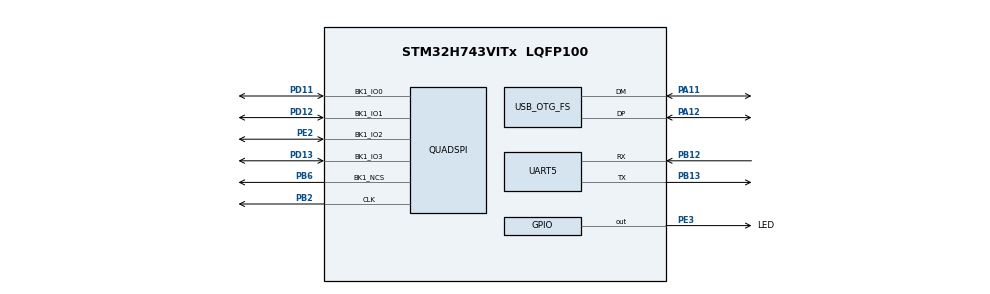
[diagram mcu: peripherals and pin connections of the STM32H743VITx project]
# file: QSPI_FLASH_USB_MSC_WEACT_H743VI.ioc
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CORTEX_M7.AccessPermission_S-Cortex_Memory_Protection_Unit_Region1_Settings_S=MPU_REGION_FULL_ACCESS
CORTEX_M7.BaseAddress_S-Cortex_Memory_Protection_Unit_Region1_Settings_S=0x90000000
CORTEX_M7.Enable_S-Cortex_Memory_Protection_Unit_Region1_Settings_S=MPU_REGION_ENABLE
CORTEX_M7.Size_S-Cortex_Memory_Protection_Unit_Region1_Settings_S=MPU_REGION_SIZE_8MB
CORTEX_M7.default_mode_Activation=1
Mcu.Family=STM32H7
Mcu.Name=STM32H743VITx
Mcu.Package=LQFP100
NVIC.OTG_FS_IRQn=true\:0\:0\:false\:false\:true\:false\:true\:true
NVIC.PriorityGroup=NVIC_PRIORITYGROUP_4
PA11.Mode=Device_Only
PA11.Signal=USB_OTG_FS_DM
PA12.Mode=Device_Only
PA12.Signal=USB_OTG_FS_DP
PB12.Mode=Asynchronous
PB12.Signal=UART5_RX
PB13.Mode=Asynchronous
PB13.Signal=UART5_TX
PB2.GPIO_Speed=GPIO_SPEED_FREQ_VERY_HIGH
PB2.Mode=Single Bank 1
PB2.Signal=QUADSPI_CLK
PB6.GPIO_FM6=SYSCFG_PMCR_I2C_PB6_FMP
PB6.GPIO_Speed=GPIO_SPEED_FREQ_VERY_HIGH
PB6.Mode=Single Bank 1
PB6.Signal=QUADSPI_BK1_NCS
PC14-OSC32_IN\ (OSC32_IN).Mode=LSE-External-Oscillator
PC14-OSC32_IN\ (OSC32_IN).Signal=RCC_OSC32_IN
PC15-OSC32_OUT\ (OSC32_OUT).Mode=LSE-External-Oscillator
PC15-OSC32_OUT\ (OSC32_OUT).Signal=RCC_OSC32_OUT
PD11.GPIO_Speed=GPIO_SPEED_FREQ_VERY_HIGH
PD11.Mode=Single Bank 1
PD11.Signal=QUADSPI_BK1_IO0
PD12.GPIO_Speed=GPIO_SPEED_FREQ_VERY_HIGH
PD12.Mode=Single Bank 1
PD12.Signal=QUADSPI_BK1_IO1
PD13.GPIO_Speed=GPIO_SPEED_FREQ_VERY_HIGH
PD13.Mode=Single Bank 1
PD13.Signal=QUADSPI_BK1_IO3
PE2.GPIO_Speed=GPIO_SPEED_FREQ_VERY_HIGH
PE2.Mode=Single Bank 1
PE2.Signal=QUADSPI_BK1_IO2
PE3.GPIO_Label=LED
PE3.Signal=GPIO_Output
PH0-OSC_IN\ (PH0).Mode=HSE-External-Oscillator
PH0-OSC_IN\ (PH0).Signal=RCC_OSC_IN
PH1-OSC_OUT\ (PH1).Mode=HSE-External-Oscillator
PH1-OSC_OUT\ (PH1).Signal=RCC_OSC_OUT
ProjectManager.HeapSize=0x200
ProjectManager.StackSize=0x2000
ProjectManager.TargetToolchain=STM32CubeIDE
QUADSPI.ClockPrescaler=2-1
QUADSPI.FlashSize=23-1
QUADSPI.SampleShifting=QSPI_SAMPLE_SHIFTING_HALFCYCLE
RCC.ADCFreq_Value=480000000
RCC.APB1Freq_Value=120000000
RCC.APB2Freq_Value=120000000
RCC.APB3Freq_Value=120000000
RCC.APB4Freq_Value=120000000
RCC.CortexFreq_Value=480000000
RCC.D1PPRE=RCC_APB3_DIV2
RCC.D2PPRE1=RCC_APB1_DIV2
RCC.D2PPRE2=RCC_APB2_DIV2
RCC.D3PPRE=RCC_APB4_DIV2
RCC.DIVM1=5
RCC.DIVM2=5
RCC.DIVM3=5
RCC.DIVN1=192
RCC.DIVN2=192
RCC.DIVN3=192
RCC.DIVQ1=20
RCC.DIVQ2=8
RCC.DIVQ3=8
RCC.DIVR2=8
RCC.HCLKFreq_Value=240000000
RCC.HPRE=RCC_HCLK_DIV2
RCC.PLLFRACN=0
RCC.PLLSourceVirtual=RCC_PLLSOURCE_HSE
RCC.QSPICLockSelection=RCC_QSPICLKSOURCE_PLL2
RCC.SYSCLKFreq_VALUE=480000000
RCC.SYSCLKSource=RCC_SYSCLKSOURCE_PLLCLK
RCC.USBFreq_Value=48000000
USB_DEVICE.CLASS_NAME_FS=MSC
USB_DEVICE.MSC_MEDIA_PACKET-MSC_FS=512
USB_DEVICE.VirtualMode-MSC_FS=Msc
USB_DEVICE.VirtualModeFS=Msc_FS
USB_OTG_FS.VirtualMode=Device_Only
USB_OTG_FS.dma_enable=ENABLE
VP_MEMORYMAP_VS_MEMORYMAP.Mode=CurAppReg
VP_USB_DEVICE_VS_USB_DEVICE_MSC_FS.Mode=MSC_FS
board=custom

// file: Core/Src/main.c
/* USER CODE BEGIN Header */
/**
  ******************************************************************************
  * @file           : main.c
  * @brief          : Main program body
  ******************************************************************************
  * @attention
  *
  * Copyright (c) 2026 STMicroelectronics.
  * All rights reserved.
  *
  * This software is licensed under terms that can be found in the LICENSE file
  * in the root directory of this software component.
  * If no LICENSE file comes with this software, it is provided AS-IS.
  *
  ******************************************************************************
  */
/* USER CODE END Header */
#include "main.h"
#include "usb_device.h"

/* USER CODE BEGIN Includes */
#include <stdio.h>
#include "w25qxx_qspi.h"
/* USER CODE END Includes */

QSPI_HandleTypeDef hqspi;

UART_HandleTypeDef huart5;

void SystemClock_Config(void);
static void MPU_Config(void);
static void MX_GPIO_Init(void);
static void MX_QUADSPI_Init(void);
static void MX_UART5_Init(void);
/* USER CODE BEGIN PFP */
void W25QXX_Demo(void);
/* USER CODE END PFP */

/* USER CODE BEGIN 0 */
void LED_Blink(uint32_t delay)
{
	HAL_GPIO_WritePin(LED_GPIO_Port,LED_Pin,GPIO_PIN_SET);
	HAL_Delay(delay - 1);
	HAL_GPIO_WritePin(LED_GPIO_Port,LED_Pin,GPIO_PIN_RESET);
	HAL_Delay(500-1);
}
/* USER CODE END 0 */

int main(void)
{

  /* MPU Configuration--------------------------------------------------------*/
  MPU_Config();

  /* MCU Configuration--------------------------------------------------------*/

  /* Reset of all peripherals, Initializes the Flash interface and the Systick. */
  HAL_Init();

  /* Configure the system clock */
  SystemClock_Config();

  /* Initialize all configured peripherals */
  MX_GPIO_Init();
  MX_QUADSPI_Init();
  MX_UART5_Init();
  MX_USB_DEVICE_Init();
  /* USER CODE BEGIN 2 */

  //W25QXX_Demo();

  /* USER CODE END 2 */

  /* Infinite loop */
  while (1)
  {

    /* USER CODE BEGIN 3 */
	LED_Blink(5);
  }
  /* USER CODE END 3 */
}

void SystemClock_Config(void)
{
  RCC_OscInitTypeDef RCC_OscInitStruct = {0};
  RCC_ClkInitTypeDef RCC_ClkInitStruct = {0};

  /** Supply configuration update enable
  */
  HAL_PWREx_ConfigSupply(PWR_LDO_SUPPLY);

  /** Configure the main internal regulator output voltage
  */
  __HAL_PWR_VOLTAGESCALING_CONFIG(PWR_REGULATOR_VOLTAGE_SCALE0);

  while(!__HAL_PWR_GET_FLAG(PWR_FLAG_VOSRDY)) {}

  /** Initializes the RCC Oscillators according to the specified parameters
  * in the RCC_OscInitTypeDef structure.
  */
  RCC_OscInitStruct.OscillatorType = RCC_OSCILLATORTYPE_HSE;
  RCC_OscInitStruct.HSEState = RCC_HSE_ON;
  RCC_OscInitStruct.PLL.PLLState = RCC_PLL_ON;
  RCC_OscInitStruct.PLL.PLLSource = RCC_PLLSOURCE_HSE;
  RCC_OscInitStruct.PLL.PLLM = 5;
  RCC_OscInitStruct.PLL.PLLN = 192;
  RCC_OscInitStruct.PLL.PLLP = 2;
  RCC_OscInitStruct.PLL.PLLQ = 20;
  RCC_OscInitStruct.PLL.PLLR = 2;
  RCC_OscInitStruct.PLL.PLLRGE = RCC_PLL1VCIRANGE_2;
  RCC_OscInitStruct.PLL.PLLVCOSEL = RCC_PLL1VCOWIDE;
  RCC_OscInitStruct.PLL.PLLFRACN = 0;
  if (HAL_RCC_OscConfig(&RCC_OscInitStruct) != HAL_OK)
  {
    Error_Handler();
  }

  /** Initializes the CPU, AHB and APB buses clocks
  */
  RCC_ClkInitStruct.ClockType = RCC_CLOCKTYPE_HCLK|RCC_CLOCKTYPE_SYSCLK
                              |RCC_CLOCKTYPE_PCLK1|RCC_CLOCKTYPE_PCLK2
                              |RCC_CLOCKTYPE_D3PCLK1|RCC_CLOCKTYPE_D1PCLK1;
  RCC_ClkInitStruct.SYSCLKSource = RCC_SYSCLKSOURCE_PLLCLK;
  RCC_ClkInitStruct.SYSCLKDivider = RCC_SYSCLK_DIV1;
  RCC_ClkInitStruct.AHBCLKDivider = RCC_HCLK_DIV2;
  RCC_ClkInitStruct.APB3CLKDivider = RCC_APB3_DIV2;
  RCC_ClkInitStruct.APB1CLKDivider = RCC_APB1_DIV2;
  RCC_ClkInitStruct.APB2CLKDivider = RCC_APB2_DIV2;
  RCC_ClkInitStruct.APB4CLKDivider = RCC_APB4_DIV2;

  if (HAL_RCC_ClockConfig(&RCC_ClkInitStruct, FLASH_LATENCY_4) != HAL_OK)
  {
    Error_Handler();
  }
}

static void MX_QUADSPI_Init(void)
{

  /* QUADSPI parameter configuration*/
  hqspi.Instance = QUADSPI;
  hqspi.Init.ClockPrescaler = 2-1;
  hqspi.Init.FifoThreshold = 1;
  hqspi.Init.SampleShifting = QSPI_SAMPLE_SHIFTING_HALFCYCLE;
  hqspi.Init.FlashSize = 23-1;
  hqspi.Init.ChipSelectHighTime = QSPI_CS_HIGH_TIME_1_CYCLE;
  hqspi.Init.ClockMode = QSPI_CLOCK_MODE_0;
  hqspi.Init.FlashID = QSPI_FLASH_ID_1;
  hqspi.Init.DualFlash = QSPI_DUALFLASH_DISABLE;
  if (HAL_QSPI_Init(&hqspi) != HAL_OK)
  {
    Error_Handler();
  }

}

static void MX_UART5_Init(void)
{

  huart5.Instance = UART5;
  huart5.Init.BaudRate = 115200;
  huart5.Init.WordLength = UART_WORDLENGTH_8B;
  huart5.Init.StopBits = UART_STOPBITS_1;
  huart5.Init.Parity = UART_PARITY_NONE;
  huart5.Init.Mode = UART_MODE_TX_RX;
  huart5.Init.HwFlowCtl = UART_HWCONTROL_NONE;
  huart5.Init.OverSampling = UART_OVERSAMPLING_16;
  huart5.Init.OneBitSampling = UART_ONE_BIT_SAMPLE_DISABLE;
  huart5.Init.ClockPrescaler = UART_PRESCALER_DIV1;
  huart5.AdvancedInit.AdvFeatureInit = UART_ADVFEATURE_NO_INIT;
  if (HAL_UART_Init(&huart5) != HAL_OK)
  {
    Error_Handler();
  }
  if (HAL_UARTEx_SetTxFifoThreshold(&huart5, UART_TXFIFO_THRESHOLD_1_8) != HAL_OK)
  {
    Error_Handler();
  }
  if (HAL_UARTEx_SetRxFifoThreshold(&huart5, UART_RXFIFO_THRESHOLD_1_8) != HAL_OK)
  {
    Error_Handler();
  }
  if (HAL_UARTEx_DisableFifoMode(&huart5) != HAL_OK)
  {
    Error_Handler();
  }

}

static void MX_GPIO_Init(void)
{
  GPIO_InitTypeDef GPIO_InitStruct = {0};

  /* GPIO Ports Clock Enable */
  __HAL_RCC_GPIOE_CLK_ENABLE();
  __HAL_RCC_GPIOC_CLK_ENABLE();
  __HAL_RCC_GPIOH_CLK_ENABLE();
  __HAL_RCC_GPIOB_CLK_ENABLE();
  __HAL_RCC_GPIOD_CLK_ENABLE();
  __HAL_RCC_GPIOA_CLK_ENABLE();

  /*Configure GPIO pin Output Level */
  HAL_GPIO_WritePin(LED_GPIO_Port, LED_Pin, GPIO_PIN_RESET);

  /*Configure GPIO pin : LED_Pin */
  GPIO_InitStruct.Pin = LED_Pin;
  GPIO_InitStruct.Mode = GPIO_MODE_OUTPUT_PP;
  GPIO_InitStruct.Pull = GPIO_NOPULL;
  GPIO_InitStruct.Speed = GPIO_SPEED_FREQ_LOW;
  HAL_GPIO_Init(LED_GPIO_Port, &GPIO_InitStruct);

}

 /* MPU Configuration */

void MPU_Config(void)
{
  MPU_Region_InitTypeDef MPU_InitStruct = {0};

  /* Disables the MPU */
  HAL_MPU_Disable();

  /** Initializes and configures the Region and the memory to be protected
  */
  MPU_InitStruct.Enable = MPU_REGION_ENABLE;
  MPU_InitStruct.Number = MPU_REGION_NUMBER0;
  MPU_InitStruct.BaseAddress = 0x0;
  MPU_InitStruct.Size = MPU_REGION_SIZE_4GB;
  MPU_InitStruct.SubRegionDisable = 0x87;
  MPU_InitStruct.TypeExtField = MPU_TEX_LEVEL0;
  MPU_InitStruct.AccessPermission = MPU_REGION_NO_ACCESS;
  MPU_InitStruct.DisableExec = MPU_INSTRUCTION_ACCESS_DISABLE;
  MPU_InitStruct.IsShareable = MPU_ACCESS_SHAREABLE;
  MPU_InitStruct.IsCacheable = MPU_ACCESS_NOT_CACHEABLE;
  MPU_InitStruct.IsBufferable = MPU_ACCESS_NOT_BUFFERABLE;

  HAL_MPU_ConfigRegion(&MPU_InitStruct);

  /** Initializes and configures the Region and the memory to be protected
  */
  MPU_InitStruct.Number = MPU_REGION_NUMBER1;
  MPU_InitStruct.BaseAddress = 0x90000000;
  MPU_InitStruct.Size = MPU_REGION_SIZE_8MB;
  MPU_InitStruct.SubRegionDisable = 0x0;
  MPU_InitStruct.AccessPermission = MPU_REGION_FULL_ACCESS;
  MPU_InitStruct.DisableExec = MPU_INSTRUCTION_ACCESS_ENABLE;
  MPU_InitStruct.IsShareable = MPU_ACCESS_NOT_SHAREABLE;

  HAL_MPU_ConfigRegion(&MPU_InitStruct);
  /* Enables the MPU */
  HAL_MPU_Enable(MPU_PRIVILEGED_DEFAULT);

}

void Error_Handler(void)
{
  __disable_irq();
  while (1)
  {
  }
}
